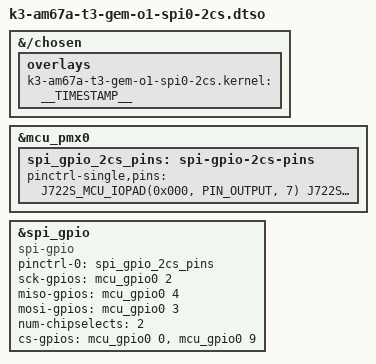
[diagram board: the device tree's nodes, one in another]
// SPDX-License-Identifier: GPL-2.0
/*
 * DT Overlay for spi0-2cs on t3-gem-o1 board.
 *
 * Copyright (C) 2023 Texas Instruments Incorporated - https://www.ti.com/
 *
 */

/dts-v1/;
/plugin/;

#include <dt-bindings/gpio/gpio.h>
#include "k3-pinctrl.h"

/*
 * Helper to show loaded overlays under: /proc/device-tree/chosen/overlays/
 */
&{/chosen} {
	overlays {
		k3-am67a-t3-gem-o1-spi0-2cs.kernel = __TIMESTAMP__;
	};
};

&mcu_pmx0 {
	spi_gpio_2cs_pins: spi-gpio-2cs-pins {
		pinctrl-single,pins = <
			J722S_MCU_IOPAD(0x000, PIN_OUTPUT, 7)	/* (C12) MCU_SPI0_CS0.MCU_GPIO0_0 SS 0 */
			J722S_MCU_IOPAD(0x024, PIN_OUTPUT, 7)	/* (B3) WKUP_UART0_RXD.MCU_GPIO0_9 SS 1 */
			J722S_MCU_IOPAD(0x008, PIN_OUTPUT, 7)	/* (A9) MCU_SPI0_CLK.MCU_GPIO0_2 SCLK */
			J722S_MCU_IOPAD(0x010, PIN_INPUT, 7)	/* (C11) MCU_SPI0_D1.MCU_GPIO0_4 MISO */
			J722S_MCU_IOPAD(0x00C, PIN_OUTPUT, 7)	/* (B12) MCU_SPI0_D0.MCU_GPIO0_3 MOSI */
		>;
	};
};

&spi_gpio {
	compatible = "spi-gpio";
	#address-cells = <0x1>;
	#size-cells = <0x0>;
	pinctrl-names = "default";
	pinctrl-0 = <&spi_gpio_2cs_pins>;

	sck-gpios = <&mcu_gpio0 2 GPIO_ACTIVE_HIGH>;
	miso-gpios = <&mcu_gpio0 4 GPIO_ACTIVE_HIGH>;
	mosi-gpios = <&mcu_gpio0 3 GPIO_ACTIVE_HIGH>;

	num-chipselects = <2>;
	cs-gpios = <
		&mcu_gpio0 0 GPIO_ACTIVE_HIGH
		&mcu_gpio0 9 GPIO_ACTIVE_HIGH
	>;

	status = "okay";
};
